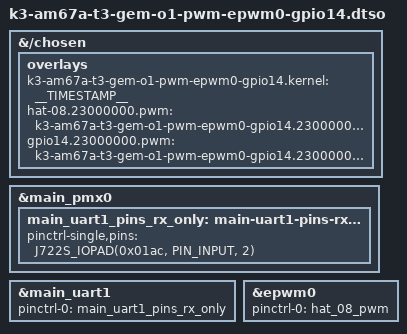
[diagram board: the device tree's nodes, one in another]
// SPDX-License-Identifier: GPL-2.0-only OR MIT
/*
 * DT Overlay to use GPIO14 (PWM1) within the expansion header for EPWM0 (pwmchip3).
 *
 * This overlay disables TX pin of main_uart1 (GPIO14) because it conflicts with PWM1.
 * main_uart1 is left half duplex (RX only) while this overlay is loaded.
 *
 * WARNING: do not load together with k3-am67a-t3-gem-o1-pwm-epwm0-gpio5.dtso.
 * Both set &epwm0's pinctrl-0, which is single valued, so the one applied last
 * silently wins and the other pad is never muxed - with no error anywhere. Use
 * k3-am67a-t3-gem-o1-pwm-epwm0-gpio5-gpio14.dtso to get both outputs.
 *
 * Copyright (C) 2023 Texas Instruments Incorporated - https://www.ti.com/
 */

/dts-v1/;
/plugin/;

#include <dt-bindings/gpio/gpio.h>
#include "k3-pinctrl.h"

/*
 * Helper to show loaded overlays under: /proc/device-tree/chosen/overlays/
*/
&{/chosen} {
	overlays {
		k3-am67a-t3-gem-o1-pwm-epwm0-gpio14.kernel = __TIMESTAMP__;
		hat-08.23000000.pwm = "k3-am67a-t3-gem-o1-pwm-epwm0-gpio14.23000000.1.GPIO14";
		gpio14.23000000.pwm = "k3-am67a-t3-gem-o1-pwm-epwm0-gpio14.23000000.1.GPIO14";
	};
};

/*
 * hat_08_pwm is defined in k3-am67a-t3-gem-o1-pinmux.dtsi and is part of the
 * base DTB, so it is only referenced below, never redefined. Redefining a base
 * pin group from an overlay merges into it and silently overrides
 * pinctrl-single,pins, which would make the pinmux.dtsi definition dead.
 * main_uart1_pins_rx_only has no base counterpart, so it stays here.
 */
&main_pmx0 {
	main_uart1_pins_rx_only: main-uart1-pins-rx-only {
		pinctrl-single,pins = <
			J722S_IOPAD(0x01ac, PIN_INPUT, 2) /* (C27) MCASP0_AFSR.UART1_RXD */
		>;
	};
};

&main_uart1 {
	pinctrl-0 = <&main_uart1_pins_rx_only>;
};

&epwm0 {
	pinctrl-names = "default";
	pinctrl-0 = <&hat_08_pwm>;
	status = "okay";
};
